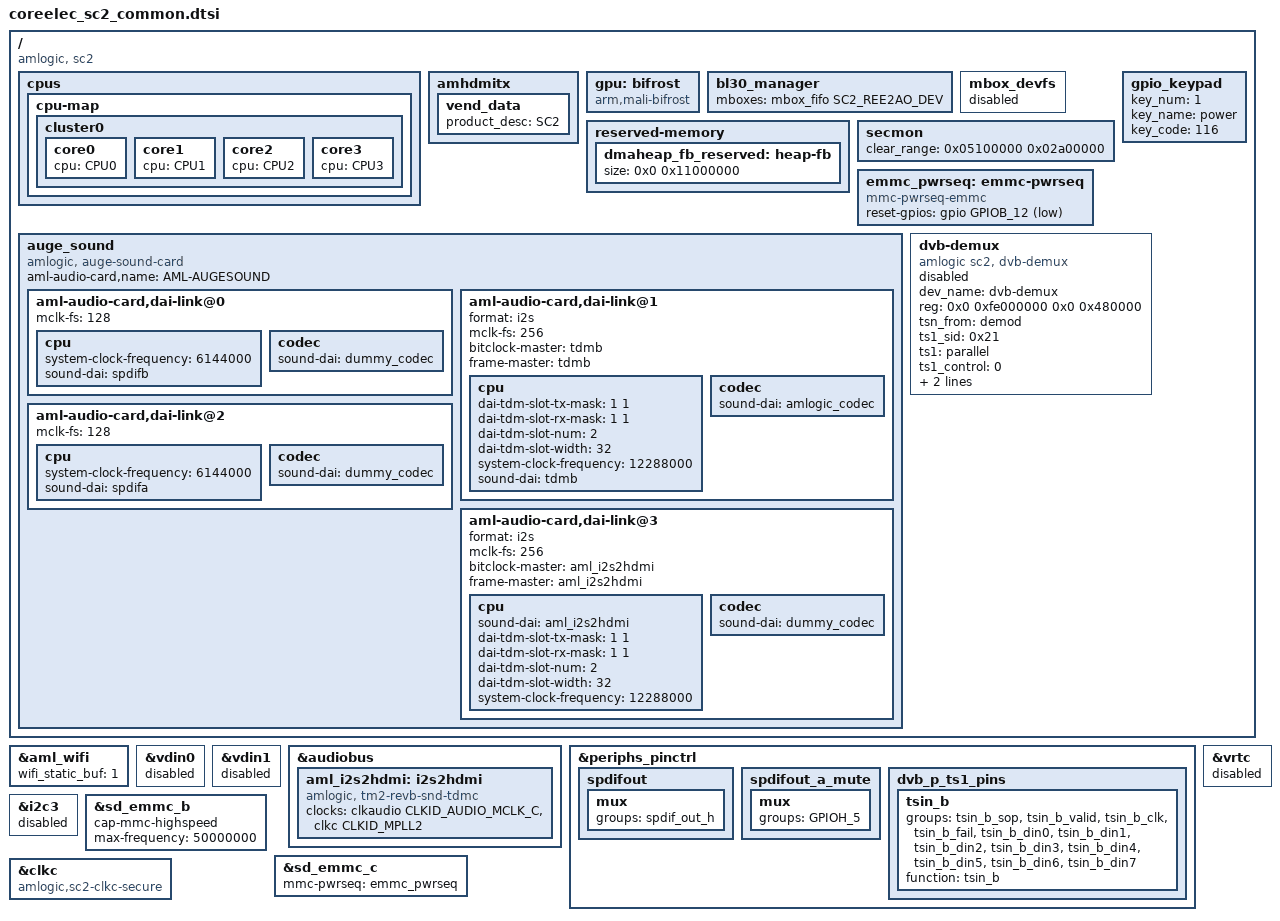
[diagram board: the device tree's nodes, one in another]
#include "coreelec_common.dtsi"

/ {
	compatible = "amlogic, sc2";

	cpus:cpus {
		cpu-map {
			cluster0:cluster0 {
				core0 {
					cpu = <&CPU0>;
				};
				core1 {
					cpu = <&CPU1>;
				};
				core2 {
					cpu = <&CPU2>;
				};
				core3 {
					cpu = <&CPU3>;
				};
			};
		};
	};

	amhdmitx: amhdmitx{
		vend_data: vend_data{ /* Should modified by Customer */
			product_desc = "SC2"; /* Max Chars: 16 */
		};
	};

	gpu:bifrost {
		compatible = "arm,mali-bifrost";
	};

	bl30_manager {
		mboxes = <&mbox_fifo SC2_REE2AO_DEV>;
	};

	mbox_devfs {
		status = "disabled";
	};

	gpu:bifrost {
		compatible = "arm,mali-bifrost";
	};

	reserved-memory {
		dmaheap_fb_reserved:heap-fb {
			size = <0x0 0x11000000>;
		};
	};

	secmon {
		clear_range = <0x05100000 0x02a00000>;
	};

	emmc_pwrseq: emmc-pwrseq {
		compatible = "mmc-pwrseq-emmc";
		reset-gpios = <&gpio GPIOB_12 GPIO_ACTIVE_LOW>;
	};

	/delete-node/ auge_sound;
	auge_sound {
		compatible = "amlogic, auge-sound-card";
		aml-audio-card,name = "AML-AUGESOUND";

		aml-audio-card,dai-link@0 {
			mclk-fs = <128>;
			cpu {
				system-clock-frequency = <6144000>;
				sound-dai = <&spdifb>;
			};
			codec {
				sound-dai = <&dummy_codec>;
			};
		};

		aml-audio-card,dai-link@1 {
			format = "i2s";
			mclk-fs = <256>;
			bitclock-master = <&tdmb>;
			frame-master = <&tdmb>;
			cpu {
				dai-tdm-slot-tx-mask = <1 1>;
				dai-tdm-slot-rx-mask = <1 1>;
				dai-tdm-slot-num = <2>;
				dai-tdm-slot-width = <32>;
				system-clock-frequency = <12288000>;
				sound-dai = <&tdmb>;
			};
			codec {
				sound-dai = <&amlogic_codec>;
			};
		};

		aml-audio-card,dai-link@2 {
			mclk-fs = <128>;
			cpu {
				system-clock-frequency = <6144000>;
				sound-dai = <&spdifa>;
			};
			codec {
				sound-dai = <&dummy_codec>;
			};
		};

		aml-audio-card,dai-link@3 {
			format = "i2s";
			mclk-fs = <256>;
			bitclock-master = <&aml_i2s2hdmi>;
			frame-master = <&aml_i2s2hdmi>;
			cpu {
				sound-dai = <&aml_i2s2hdmi>;
				dai-tdm-slot-tx-mask = <1 1>;
				dai-tdm-slot-rx-mask = <1 1>;
				dai-tdm-slot-num = <2>;
				dai-tdm-slot-width = <32>;
				system-clock-frequency = <12288000>;
			};
			codec {
				sound-dai = <&dummy_codec>;
			};
		};
	};

	gpio_keypad {
		key_num = <1>;
		key_name = "power";
		key_code = <116>;
	};

	/delete-node/ gpio_leds;

	dvb-demux {
		compatible = "amlogic sc2, dvb-demux";
		dev_name = "dvb-demux";
		status = "disabled";

		reg = <0x0 0xfe000000 0x0 0x480000>;

		tsn_from = "demod";

		ts1_sid = <0x21>;
		ts1 = "parallel";
		ts1_control = <0>;
		ts1_invert = <0>;

		pinctrl-names = "p_ts1";
		pinctrl-0 = <&dvb_p_ts1_pins>;
	};
};

&aml_wifi {
	wifi_static_buf = <1>;
};

&vdin0 {
	status = "disabled";
};

&vdin1 {
	status = "disabled";
};

&audiobus {
	/delete-node/ tdmc;
	/delete-node/ tdm@2;

	aml_i2s2hdmi: i2s2hdmi {
		compatible = "amlogic, tm2-revb-snd-tdmc";
		clocks = <&clkaudio CLKID_AUDIO_MCLK_C
				&clkc CLKID_MPLL2>;
		clock-names = "mclk", "clk_srcpll";
	};
};

&periphs_pinctrl {
	spdifout: spdifout {
		mux { /* GPIOH_4 */
			groups = "spdif_out_h";
		};
	};

	spdifout_a_mute: spdifout_a_mute {
		mux { /* GPIOH_5 */
			groups = "GPIOH_5";
		};
	};

	dvb_p_ts1_pins: dvb_p_ts1_pins {
		tsin_b {
			groups = "tsin_b_sop",
			"tsin_b_valid",
			"tsin_b_clk",
			"tsin_b_fail",
			"tsin_b_din0",
			"tsin_b_din1",
			"tsin_b_din2",
			"tsin_b_din3",
			"tsin_b_din4",
			"tsin_b_din5",
			"tsin_b_din6",
			"tsin_b_din7";
			function = "tsin_b";
		};
	};
};

&vrtc {
	status = "disabled";
};

&i2c3 {
	status = "disabled";
	/delete-node/ tlc59116@60;
	/delete-node/ aw9523_led@5b;
};

&sd_emmc_b {
	status = "okay";
	cap-mmc-highspeed;
	max-frequency = <50000000>;
};

&sd_emmc_c {
	mmc-pwrseq = <&emmc_pwrseq>;
};

&clkc {
	compatible = "amlogic,sc2-clkc-secure";
};
